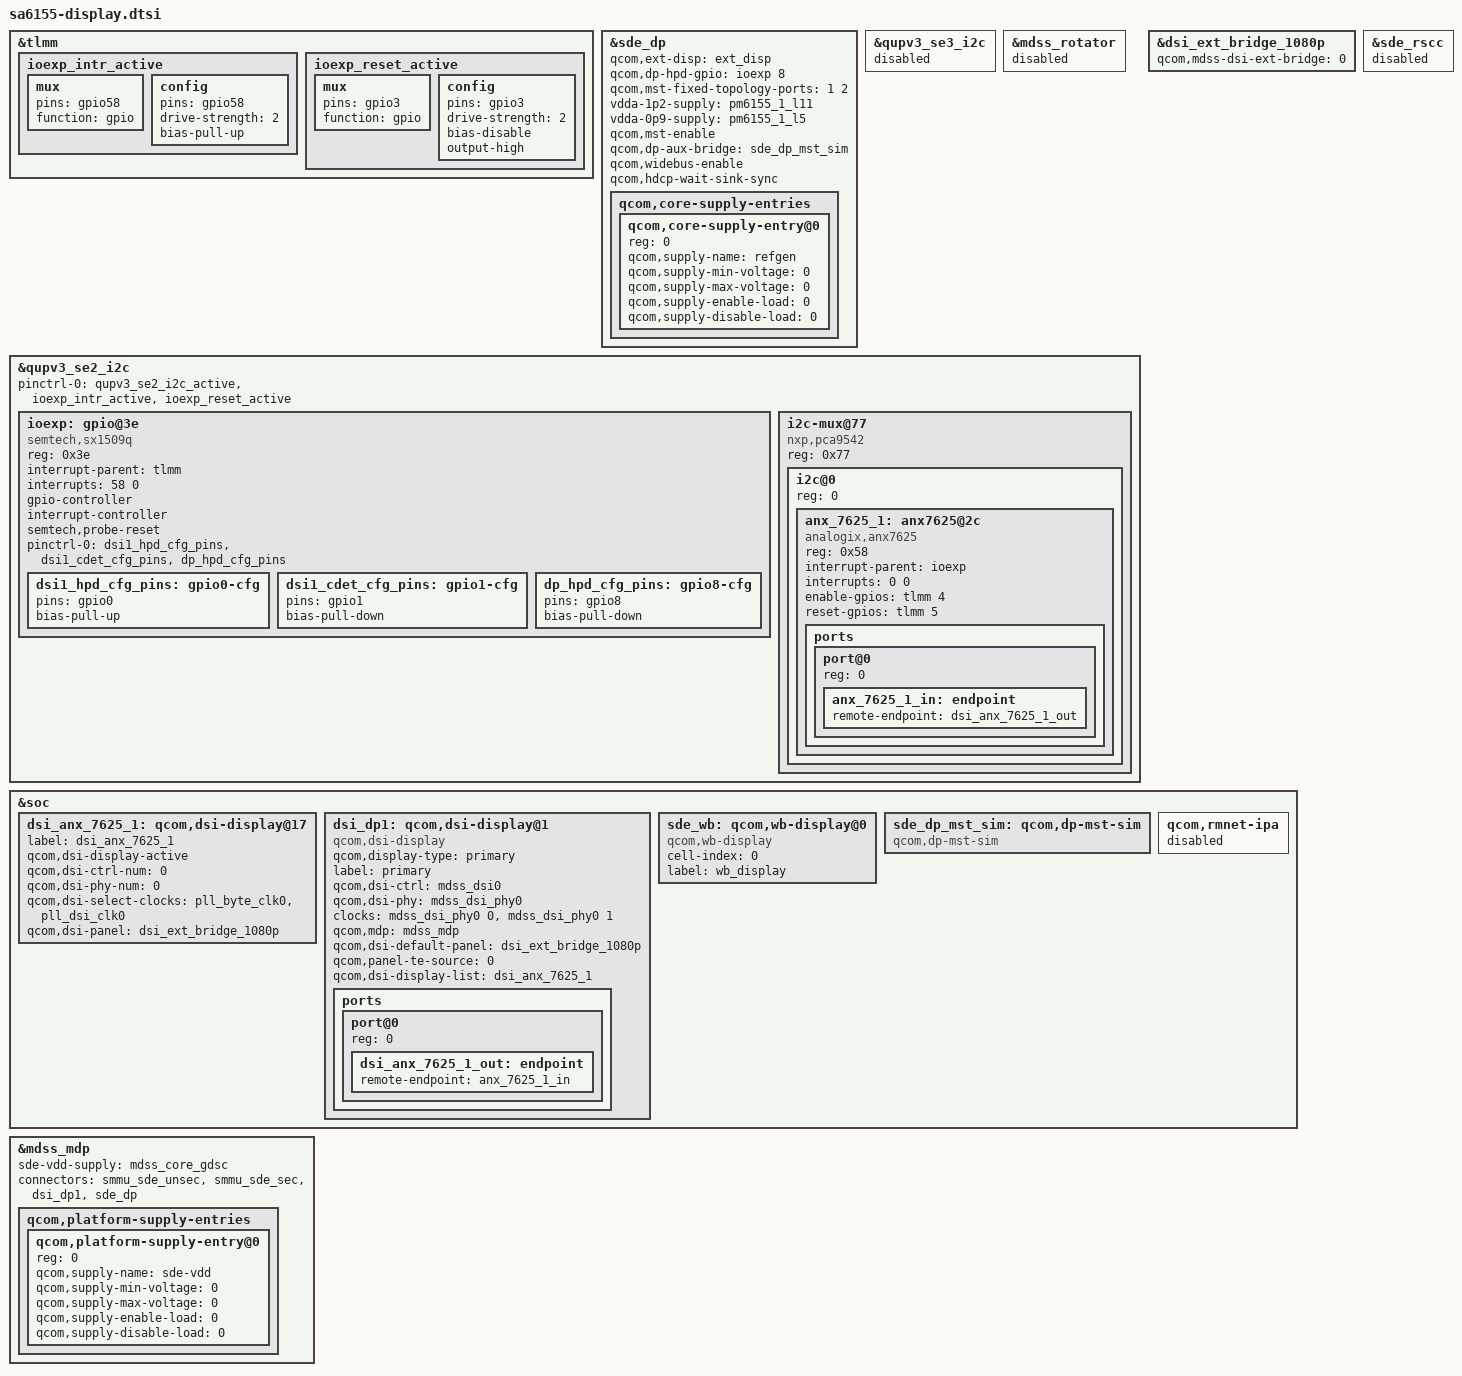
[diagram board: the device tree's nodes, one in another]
#include <dt-bindings/clock/qcom,rpmh.h>
#include "sm6150-sde.dtsi"
#include "dsi-panel-ext-bridge-1080p.dtsi"

&tlmm {
	ioexp_intr_active: ioexp_intr_active {
		mux {
			pins = "gpio58";
			function = "gpio";
		};
		config {
			pins = "gpio58";
			drive-strength = <2>;
			bias-pull-up;
		};
	};

	ioexp_reset_active: ioexp_reset_active {
		mux {
			pins = "gpio3";
			function = "gpio";
		};
		config {
			pins = "gpio3";
			drive-strength = <2>;
			bias-disable;
			output-high;
		};
	};
};

&sde_dp {
	qcom,ext-disp = <&ext_disp>;
	qcom,dp-hpd-gpio = <&ioexp 8 0>;
	qcom,mst-fixed-topology-ports = <1 2>;

	vdda-1p2-supply = <&pm6155_1_l11>;
	vdda-0p9-supply = <&pm6155_1_l5>;
	/delete-property/ qcom,dp-aux-switch;
	/delete-property/ pinctrl-names;
	qcom,mst-enable;
	qcom,dp-aux-bridge = <&sde_dp_mst_sim>;
	qcom,widebus-enable;
	qcom,hdcp-wait-sink-sync;

	qcom,core-supply-entries {
		#address-cells = <1>;
		#size-cells = <0>;
		qcom,core-supply-entry@0 {
			reg = <0>;
			qcom,supply-name = "refgen";
			qcom,supply-min-voltage = <0>;
			qcom,supply-max-voltage = <0>;
			qcom,supply-enable-load = <0>;
			qcom,supply-disable-load = <0>;
		};
	};
};

/* FSA & Rotator not required in Auto */

&qupv3_se3_i2c {
	status = "disabled";
};

&mdss_rotator {
	status = "disabled";
};

&qupv3_se2_i2c {

	status = "ok";

	pinctrl-0 = <&qupv3_se2_i2c_active
		&ioexp_intr_active
		&ioexp_reset_active>;

	ioexp: gpio@3e {
		#gpio-cells = <2>;
		#interrupt-cells = <2>;
		compatible = "semtech,sx1509q";
		reg = <0x3e>;
		interrupt-parent = <&tlmm>;
		interrupts = <58 0>;
		gpio-controller;
		interrupt-controller;
		semtech,probe-reset;

		pinctrl-names = "default";
		pinctrl-0 = <&dsi1_hpd_cfg_pins
			&dsi1_cdet_cfg_pins
			&dp_hpd_cfg_pins>;

		dsi1_hpd_cfg_pins: gpio0-cfg {
			pins = "gpio0";
			bias-pull-up;
		};

		dsi1_cdet_cfg_pins: gpio1-cfg {
			pins = "gpio1";
			bias-pull-down;
		};

		dp_hpd_cfg_pins: gpio8-cfg {
			pins = "gpio8";
			bias-pull-down;
		};
	};

	i2c-mux@77 {
		compatible = "nxp,pca9542";
		reg = <0x77>;
		#address-cells = <1>;
		#size-cells = <0>;

		i2c@0 {
			#address-cells = <1>;
			#size-cells = <0>;
			reg = <0>;

			anx_7625_1: anx7625@2c {
				compatible = "analogix,anx7625";
				reg = <0x58>;
				interrupt-parent = <&ioexp>;
				interrupts = <0 0>;
				enable-gpios = <&tlmm 4 0>;
				reset-gpios = <&tlmm 5 0>;
			};
		};
	};
};
&anx_7625_1 {
	ports {
		#address-cells = <1>;
		#size-cells = <0>;

		port@0 {
			reg = <0>;
			anx_7625_1_in: endpoint {
				remote-endpoint = <&dsi_anx_7625_1_out>;
			};
		};
	};
};

&dsi_ext_bridge_1080p {
	qcom,mdss-dsi-ext-bridge = <0>;
};

&soc {
	dsi_anx_7625_1: qcom,dsi-display@17 {
		label = "dsi_anx_7625_1";
		qcom,dsi-display-active;

		qcom,dsi-ctrl-num = <0>;
		qcom,dsi-phy-num = <0>;
		qcom,dsi-select-clocks = "pll_byte_clk0", "pll_dsi_clk0";

		qcom,dsi-panel = <&dsi_ext_bridge_1080p>;
	};

	dsi_dp1: qcom,dsi-display@1 {
		compatible = "qcom,dsi-display";
		qcom,display-type = "primary";
		label = "primary";

		qcom,dsi-ctrl = <&mdss_dsi0>;
		qcom,dsi-phy = <&mdss_dsi_phy0>;

		clocks = <&mdss_dsi_phy0 0>,
			 <&mdss_dsi_phy0 1>;
		clock-names = "pll_byte_clk0", "pll_dsi_clk0";

		qcom,mdp = <&mdss_mdp>;
		qcom,dsi-default-panel = <&dsi_ext_bridge_1080p>;
		qcom,panel-te-source = <0>;

		qcom,dsi-display-list =
			<&dsi_anx_7625_1>;

		ports {
			#address-cells = <1>;
			#size-cells = <0>;

			port@0 {
				reg = <0>;
				dsi_anx_7625_1_out: endpoint {
					remote-endpoint = <&anx_7625_1_in>;
				};
			};
		};
	};

	sde_wb: qcom,wb-display@0 {
		compatible = "qcom,wb-display";
		cell-index = <0>;
		label = "wb_display";
	};
	sde_dp_mst_sim: qcom,dp-mst-sim {
		compatible = "qcom,dp-mst-sim";
	};

	qcom,rmnet-ipa {
		status="disabled";
	};
};

&mdss_mdp {
	sde-vdd-supply = <&mdss_core_gdsc>;
	connectors = <&smmu_sde_unsec &smmu_sde_sec &dsi_dp1 &sde_dp>;

	qcom,platform-supply-entries {
		#address-cells = <1>;
		#size-cells = <0>;

		qcom,platform-supply-entry@0 {
			reg = <0>;
			qcom,supply-name = "sde-vdd";
			qcom,supply-min-voltage = <0>;
			qcom,supply-max-voltage = <0>;
			qcom,supply-enable-load = <0>;
			qcom,supply-disable-load = <0>;
		};
	};
};

&sde_rscc {
	status="disabled";
};

